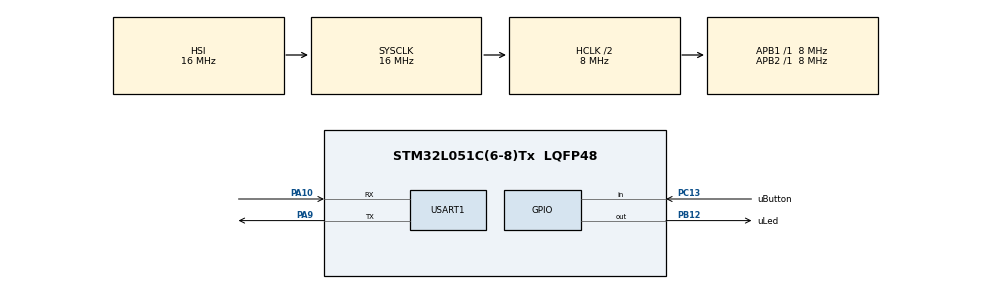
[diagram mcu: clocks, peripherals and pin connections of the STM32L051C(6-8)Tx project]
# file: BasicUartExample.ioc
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Mcu.Family=STM32L0
RCC.MSI_VALUE=2097000
PA10.Mode=Asynchronous
PC13.Signal=GPIO_Input
PC13.GPIO_Label=uButton
RCC.SYSCLKSource=RCC_SYSCLKSOURCE_HSI
ProjectManager.StackSize=0x400
USART1.VirtualMode-Asynchronous=VM_ASYNC
PA13.Signal=SYS_SWDIO
RCC.HSI16_VALUE=16000000
PA9.Mode=Asynchronous
ProjectManager.TargetToolchain=STM32CubeIDE
RCC.HCLKFreq_Value=8000000
RCC.APB2TimFreq_Value=8000000
PA9.Signal=USART1_TX
RCC.LSE_VALUE=32768
RCC.AHBFreq_Value=8000000
RCC.HSE_VALUE=8000000
board=custom
RCC.VCOOutputFreq_Value=48000000
PB12.GPIO_Label=uLed
RCC.APB2Freq_Value=8000000
PA14.Mode=Serial_Wire
RCC.AHBCLKDivider=RCC_SYSCLK_DIV2
PA13.Mode=Serial_Wire
Mcu.Name=STM32L051C(6-8)Tx
RCC.SYSCLKFreq_VALUE=16000000
Mcu.Package=LQFP48
PA10.Signal=USART1_RX
PA14.Signal=SYS_SWCLK
ProjectManager.HeapSize=0x200
RCC.HSI_VALUE=16000000
RCC.APB1TimFreq_Value=8000000
NVIC.USART1_IRQn=true\:0\:0\:false\:false\:true\:true\:true
RCC.APB1Freq_Value=8000000
PB12.Signal=GPIO_Output

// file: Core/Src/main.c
/* USER CODE BEGIN Header */
/**
  ******************************************************************************
  * @file           : main.c
  * @brief          : Main program body
  ******************************************************************************
  * @attention
  *
  * <h2><center>&copy; Copyright (c) 2022 STMicroelectronics.
  * All rights reserved.</center></h2>
  *
  * This software component is licensed by ST under BSD 3-Clause license,
  * the "License"; You may not use this file except in compliance with the
  * License. You may obtain a copy of the License at:
  *                        opensource.org/licenses/BSD-3-Clause
  *
  ******************************************************************************
  */
/* USER CODE END Header */
#include "main.h"

/* USER CODE BEGIN Includes */
#include "uartHandle.h"
/* USER CODE END Includes */

UART_HandleTypeDef huart1;

/* USER CODE BEGIN PV */
uint8_t ledFlag = 0;
/* USER CODE END PV */

void SystemClock_Config(void);
static void MX_GPIO_Init(void);
static void MX_USART1_UART_Init(void);

int main(void)
{

  /* MCU Configuration--------------------------------------------------------*/

  /* Reset of all peripherals, Initializes the Flash interface and the Systick. */
  HAL_Init();

  /* Configure the system clock */
  SystemClock_Config();

  /* Initialize all configured peripherals */
  MX_GPIO_Init();
  MX_USART1_UART_Init();
  /* USER CODE BEGIN 2 */
  HAL_UART_Receive_IT(&huart1 , &uartRxData , 1); //data alımını baslat
  /* USER CODE END 2 */

  /* Infinite loop */
  while (1)
  {

    /* USER CODE BEGIN 3 */

	  uartDataHandler();
	  if(ledFlag == 1)
	  {
		HAL_GPIO_WritePin(uLed_GPIO_Port, uLed_Pin,GPIO_PIN_SET);
	  }
	  else if(ledFlag == 0)
	  {
		HAL_GPIO_WritePin(uLed_GPIO_Port, uLed_Pin,GPIO_PIN_RESET);
	  }

  }
  /* USER CODE END 3 */
}

void SystemClock_Config(void)
{
  RCC_OscInitTypeDef RCC_OscInitStruct = {0};
  RCC_ClkInitTypeDef RCC_ClkInitStruct = {0};
  RCC_PeriphCLKInitTypeDef PeriphClkInit = {0};

  /** Configure the main internal regulator output voltage
  */
  __HAL_PWR_VOLTAGESCALING_CONFIG(PWR_REGULATOR_VOLTAGE_SCALE1);
  /** Initializes the RCC Oscillators according to the specified parameters
  * in the RCC_OscInitTypeDef structure.
  */
  RCC_OscInitStruct.OscillatorType = RCC_OSCILLATORTYPE_HSI;
  RCC_OscInitStruct.HSIState = RCC_HSI_ON;
  RCC_OscInitStruct.HSICalibrationValue = RCC_HSICALIBRATION_DEFAULT;
  RCC_OscInitStruct.PLL.PLLState = RCC_PLL_NONE;
  if (HAL_RCC_OscConfig(&RCC_OscInitStruct) != HAL_OK)
  {
    Error_Handler();
  }
  /** Initializes the CPU, AHB and APB buses clocks
  */
  RCC_ClkInitStruct.ClockType = RCC_CLOCKTYPE_HCLK|RCC_CLOCKTYPE_SYSCLK
                              |RCC_CLOCKTYPE_PCLK1|RCC_CLOCKTYPE_PCLK2;
  RCC_ClkInitStruct.SYSCLKSource = RCC_SYSCLKSOURCE_HSI;
  RCC_ClkInitStruct.AHBCLKDivider = RCC_SYSCLK_DIV2;
  RCC_ClkInitStruct.APB1CLKDivider = RCC_HCLK_DIV1;
  RCC_ClkInitStruct.APB2CLKDivider = RCC_HCLK_DIV1;

  if (HAL_RCC_ClockConfig(&RCC_ClkInitStruct, FLASH_LATENCY_0) != HAL_OK)
  {
    Error_Handler();
  }
  PeriphClkInit.PeriphClockSelection = RCC_PERIPHCLK_USART1;
  PeriphClkInit.Usart1ClockSelection = RCC_USART1CLKSOURCE_PCLK2;
  if (HAL_RCCEx_PeriphCLKConfig(&PeriphClkInit) != HAL_OK)
  {
    Error_Handler();
  }
}

static void MX_USART1_UART_Init(void)
{

  huart1.Instance = USART1;
  huart1.Init.BaudRate = 115200;
  huart1.Init.WordLength = UART_WORDLENGTH_8B;
  huart1.Init.StopBits = UART_STOPBITS_1;
  huart1.Init.Parity = UART_PARITY_NONE;
  huart1.Init.Mode = UART_MODE_TX_RX;
  huart1.Init.HwFlowCtl = UART_HWCONTROL_NONE;
  huart1.Init.OverSampling = UART_OVERSAMPLING_16;
  huart1.Init.OneBitSampling = UART_ONE_BIT_SAMPLE_DISABLE;
  huart1.AdvancedInit.AdvFeatureInit = UART_ADVFEATURE_NO_INIT;
  if (HAL_UART_Init(&huart1) != HAL_OK)
  {
    Error_Handler();
  }

}

static void MX_GPIO_Init(void)
{
  GPIO_InitTypeDef GPIO_InitStruct = {0};

  /* GPIO Ports Clock Enable */
  __HAL_RCC_GPIOC_CLK_ENABLE();
  __HAL_RCC_GPIOB_CLK_ENABLE();
  __HAL_RCC_GPIOA_CLK_ENABLE();

  /*Configure GPIO pin Output Level */
  HAL_GPIO_WritePin(uLed_GPIO_Port, uLed_Pin, GPIO_PIN_RESET);

  /*Configure GPIO pin : uButton_Pin */
  GPIO_InitStruct.Pin = uButton_Pin;
  GPIO_InitStruct.Mode = GPIO_MODE_INPUT;
  GPIO_InitStruct.Pull = GPIO_NOPULL;
  HAL_GPIO_Init(uButton_GPIO_Port, &GPIO_InitStruct);

  /*Configure GPIO pin : uLed_Pin */
  GPIO_InitStruct.Pin = uLed_Pin;
  GPIO_InitStruct.Mode = GPIO_MODE_OUTPUT_PP;
  GPIO_InitStruct.Pull = GPIO_NOPULL;
  GPIO_InitStruct.Speed = GPIO_SPEED_FREQ_LOW;
  HAL_GPIO_Init(uLed_GPIO_Port, &GPIO_InitStruct);

}

void Error_Handler(void)
{
  __disable_irq();
  while (1)
  {
  }
}

/************************ (C) COPYRIGHT STMicroelectronics *****END OF FILE****/
